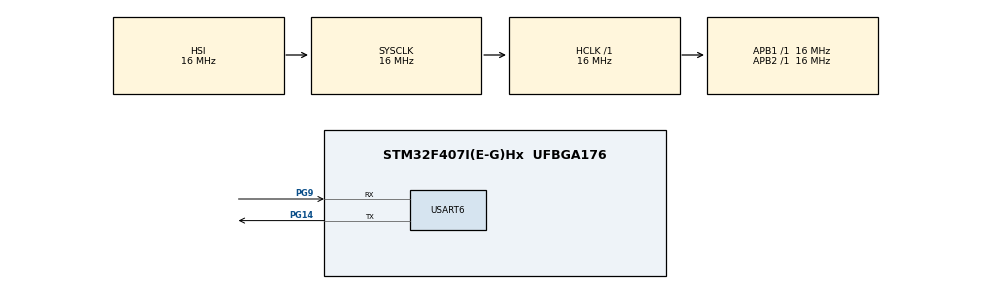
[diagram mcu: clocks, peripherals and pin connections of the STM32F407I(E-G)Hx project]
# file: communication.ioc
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Mcu.Family=STM32F4
Mcu.Name=STM32F407I(E-G)Hx
Mcu.Package=UFBGA176
NVIC.PriorityGroup=NVIC_PRIORITYGROUP_4
NVIC.USART6_IRQn=true\:0\:0\:false\:false\:true\:true\:true\:true
PA13.Mode=Serial_Wire
PA13.Signal=SYS_JTMS-SWDIO
PA14.Mode=Serial_Wire
PA14.Signal=SYS_JTCK-SWCLK
PG14.Mode=Asynchronous
PG14.Signal=USART6_TX
PG9.Mode=Asynchronous
PG9.Signal=USART6_RX
ProjectManager.HeapSize=0x200
ProjectManager.StackSize=0x400
ProjectManager.TargetToolchain=MDK-ARM V5.32
RCC.AHBFreq_Value=16000000
RCC.APB1Freq_Value=16000000
RCC.APB2Freq_Value=16000000
RCC.CortexFreq_Value=16000000
RCC.HSE_VALUE=25000000
RCC.HSI_VALUE=16000000
RCC.LSE_VALUE=32768
RCC.SYSCLKFreq_VALUE=16000000
RCC.VCOOutputFreq_Value=192000000
USART6.VirtualMode=VM_ASYNC
board=custom

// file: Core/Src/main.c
/* USER CODE BEGIN Header */
/**
  ******************************************************************************
  * @file           : main.c
  * @brief          : Main program body
  ******************************************************************************
  * @attention
  *
  * Copyright (c) 2025 STMicroelectronics.
  * All rights reserved.
  *
  * This software is licensed under terms that can be found in the LICENSE file
  * in the root directory of this software component.
  * If no LICENSE file comes with this software, it is provided AS-IS.
  *
  ******************************************************************************
  */
/* USER CODE END Header */
#include "main.h"
#include "usart.h"
#include "gpio.h"

/* USER CODE BEGIN PD */
#define FRAME_HEAD 0xAA
#define FRAME_TAIL 0x55
/* USER CODE END PD */

/* USER CODE BEGIN PV */
uint8_t rxBuffer[4];
uint8_t rxIndex = 0;
uint8_t rxByte;
volatile uint8_t frameReceived = 0;
/* USER CODE END PV */

void SystemClock_Config(void);
void UART_SendData(uint8_t data) {
    uint8_t frame[4];
    frame[0] = FRAME_HEAD;
    frame[1] = data;                    // 数据：0
    frame[2] = FRAME_HEAD + data;       // 校验和数据
    frame[3] = FRAME_TAIL;

    HAL_UART_Transmit(&huart6, frame, 7, 100);
}
// 处理接收到的数据帧
void processReceivedData(void) {
    if (frameReceived) {
        // 校验帧头和帧尾
        if (rxBuffer[0] == FRAME_HEAD && rxBuffer[3] == FRAME_TAIL) {
            uint8_t data = rxBuffer[1];
            uint8_t checksum = rxBuffer[2];

            // 校验数据
            if (checksum == (FRAME_HEAD + data)) {
                // 数据有效
                if (data == 1) {

                    // 发送响应数据0给Arduino
                    UART_SendData(1);
                }
            }
        }

        // 重置接收状态
        rxIndex = 0;
        frameReceived = 0;
    }
}

int main(void)
{

  /* MCU Configuration--------------------------------------------------------*/

  /* Reset of all peripherals, Initializes the Flash interface and the Systick. */
  HAL_Init();

  /* Configure the system clock */
  SystemClock_Config();

  /* Initialize all configured peripherals */
  MX_GPIO_Init();
  MX_USART6_UART_Init();
  /* USER CODE BEGIN 2 */
	HAL_UART_Receive_IT(&huart6, &rxByte, 1);
  /* USER CODE END 2 */

  /* Infinite loop */
  /* USER CODE BEGIN WHILE */
  while (1)
  {
	   // 处理接收到的数据
        processReceivedData();
   HAL_Delay(100);
    /* USER CODE END WHILE */

  }
}

void SystemClock_Config(void)
{
  RCC_OscInitTypeDef RCC_OscInitStruct = {0};
  RCC_ClkInitTypeDef RCC_ClkInitStruct = {0};

  /** Configure the main internal regulator output voltage
  */
  __HAL_RCC_PWR_CLK_ENABLE();
  __HAL_PWR_VOLTAGESCALING_CONFIG(PWR_REGULATOR_VOLTAGE_SCALE1);

  /** Initializes the RCC Oscillators according to the specified parameters
  * in the RCC_OscInitTypeDef structure.
  */
  RCC_OscInitStruct.OscillatorType = RCC_OSCILLATORTYPE_HSI;
  RCC_OscInitStruct.HSIState = RCC_HSI_ON;
  RCC_OscInitStruct.HSICalibrationValue = RCC_HSICALIBRATION_DEFAULT;
  RCC_OscInitStruct.PLL.PLLState = RCC_PLL_NONE;
  if (HAL_RCC_OscConfig(&RCC_OscInitStruct) != HAL_OK)
  {
    Error_Handler();
  }

  /** Initializes the CPU, AHB and APB buses clocks
  */
  RCC_ClkInitStruct.ClockType = RCC_CLOCKTYPE_HCLK|RCC_CLOCKTYPE_SYSCLK
                              |RCC_CLOCKTYPE_PCLK1|RCC_CLOCKTYPE_PCLK2;
  RCC_ClkInitStruct.SYSCLKSource = RCC_SYSCLKSOURCE_HSI;
  RCC_ClkInitStruct.AHBCLKDivider = RCC_SYSCLK_DIV1;
  RCC_ClkInitStruct.APB1CLKDivider = RCC_HCLK_DIV1;
  RCC_ClkInitStruct.APB2CLKDivider = RCC_HCLK_DIV1;

  if (HAL_RCC_ClockConfig(&RCC_ClkInitStruct, FLASH_LATENCY_0) != HAL_OK)
  {
    Error_Handler();
  }
}

/* USER CODE BEGIN 4 */
// UART接收中断回调
void HAL_UART_RxCpltCallback() {
    if (huart->Instance == USART6) {
        // 状态机接收
        if (rxIndex == 0 && rxByte == FRAME_HEAD) {
            // 检测到帧头
            rxBuffer[rxIndex++] = rxByte;
        } else if (rxIndex > 0 && rxIndex < 4) {
            rxBuffer[rxIndex++] = rxByte;

            // 接收完整帧（4字节）
            if (rxIndex == 4 && rxByte == FRAME_TAIL) {
                frameReceived = 1;
            }

            // 接收错误，重置
            if (rxIndex == 4 && rxByte != FRAME_TAIL) {
                rxIndex = 0;
            }
        } else {
            // 异常，重置
            rxIndex = 0;
        }

        // 继续接收下一个字节
        HAL_UART_Receive_IT(&huart6, &rxByte, 1);
    }
}
/* USER CODE END 4 */

void Error_Handler(void)
{
  __disable_irq();
  while (1)
  {
  }
}
